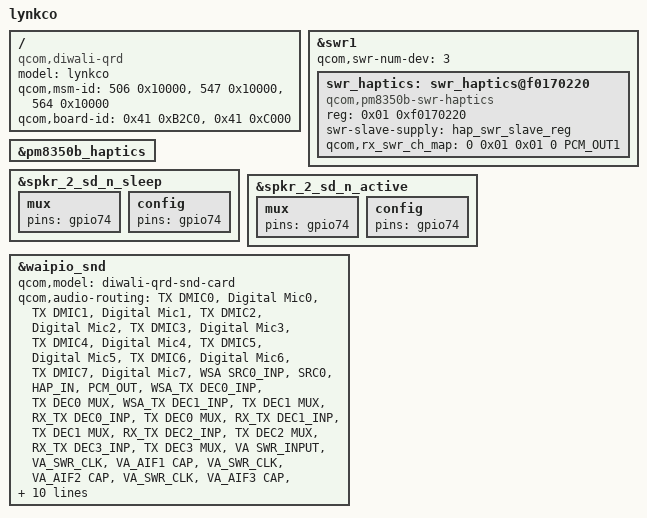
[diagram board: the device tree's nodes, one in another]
/dts-v1/;
/plugin/;

#include "diwali-audio-moto-lynkco-common.dtsi"

 / {
	model = "lynkco";
	compatible =  "qcom,diwali-qrd", "qcom,diwali", "qcom,qrd", "moto,lynkco";
	qcom,msm-id = <506 0x10000>, <547 0x10000>, <564 0x10000>;
	qcom,board-id = <0x41 0xB2C0>, <0x41 0xC000>;
};

&swr1 {
	qcom,swr-num-dev = <3>;
	swr_haptics: swr_haptics@f0170220 {
		compatible = "qcom,pm8350b-swr-haptics";
		reg = <0x01 0xf0170220>;
		swr-slave-supply = <&hap_swr_slave_reg>;
		qcom,rx_swr_ch_map = <0 0x01 0x01 0 PCM_OUT1>;
	};
};

&pm8350b_haptics {
	status = "ok";
};

&spkr_2_sd_n_sleep {
	mux {
		pins = "gpio74";
	};
	config {
		pins = "gpio74";
	};
};

&spkr_2_sd_n_active {
	mux {
		pins = "gpio74";
	};
	config {
		pins = "gpio74";
	};
};

&waipio_snd {
	qcom,model = "diwali-qrd-snd-card";
	qcom,audio-routing =
		"TX DMIC0", "Digital Mic0",
		"TX DMIC1", "Digital Mic1",
		"TX DMIC2", "Digital Mic2",
		"TX DMIC3", "Digital Mic3",
		"TX DMIC4", "Digital Mic4",
		"TX DMIC5", "Digital Mic5",
		"TX DMIC6", "Digital Mic6",
		"TX DMIC7", "Digital Mic7",
		"WSA SRC0_INP", "SRC0",
		"HAP_IN", "PCM_OUT",
		"WSA_TX DEC0_INP", "TX DEC0 MUX",
		"WSA_TX DEC1_INP", "TX DEC1 MUX",
		"RX_TX DEC0_INP", "TX DEC0 MUX",
		"RX_TX DEC1_INP", "TX DEC1 MUX",
		"RX_TX DEC2_INP", "TX DEC2 MUX",
		"RX_TX DEC3_INP", "TX DEC3 MUX",
		"VA SWR_INPUT", "VA_SWR_CLK",
		"VA_AIF1 CAP", "VA_SWR_CLK",
		"VA_AIF2 CAP", "VA_SWR_CLK",
		"VA_AIF3 CAP", "VA_SWR_CLK",
		"VA DMIC0", "Digital Mic0",
		"VA DMIC1", "Digital Mic1",
		"VA DMIC2", "Digital Mic2",
		"VA DMIC3", "Digital Mic3",
		"VA DMIC4", "Digital Mic4",
		"VA DMIC5", "Digital Mic5",
		"VA DMIC6", "Digital Mic6",
		"VA DMIC7", "Digital Mic7";

	asoc-codec = <&stub_codec>, <&lpass_cdc>,
			<&swr_haptics>,
			<&wsa883x_0221>, <&wsa883x_0222>;
	asoc-codec-names = "msm-stub-codec.1", "lpass-cdc",
			"swr-haptics",
			"wsa-codec1", "wsa-codec2";
};
